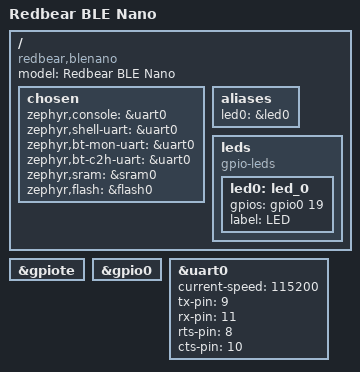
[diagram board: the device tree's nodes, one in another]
/*
 * Copyright (c) 2017 Linaro Limited
 *
 * SPDX-License-Identifier: Apache-2.0
 */

/dts-v1/;
#include <nordic/nrf51822_qfaa.dtsi>

/ {
	model = "Redbear BLE Nano";
	compatible = "redbear,blenano";

	chosen {
		zephyr,console = &uart0;
		zephyr,shell-uart = &uart0;
		zephyr,bt-mon-uart = &uart0;
		zephyr,bt-c2h-uart = &uart0;
		zephyr,sram = &sram0;
		zephyr,flash = &flash0;
	};

	aliases {
		led0 = &led0;
	};

	leds {
		compatible = "gpio-leds";
		led0: led_0 {
			gpios = <&gpio0 19 0>;
			label = "LED";
		};
	};
};

&gpiote {
	status = "okay";
};

&gpio0 {
	status = "okay";
};

&uart0 {
	current-speed = <115200>;
	status = "okay";
	tx-pin = <9>;
	rx-pin = <11>;
	rts-pin = <8>;
	cts-pin = <10>;
};
